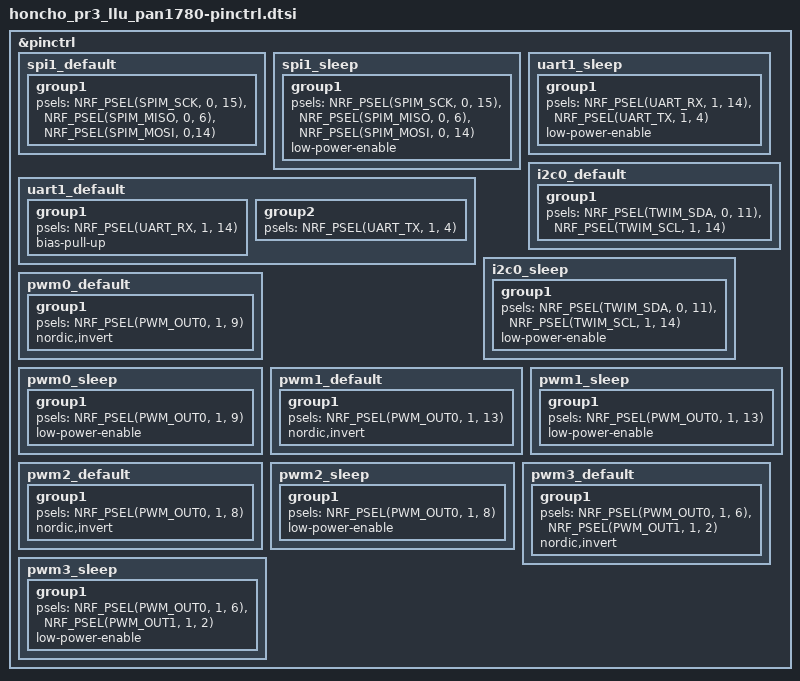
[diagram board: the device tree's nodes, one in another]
/*
 * Copyright (c) 2022 Nordic Semiconductor
 * SPDX-License-Identifier: Apache-2.0
 * Pinouts of file in path EE Team for HTAS -> Documnets 
 * -> General -> Documents -> Firmware -> Nordic Pinout.xlsx
 */
 &pinctrl {
	// uart0_default: uart0_default {
	// 	group1 {
	// 		psels = <NRF_PSEL(UART_TX, 0, 28)>,
	// 				<NRF_PSEL(UART_RX, 0, 29)>;
	// 	};
	// };

	// uart0_sleep: uart0_sleep {
	// 	group1 {
	// 		psels = <NRF_PSEL(UART_TX, 0, 28)>,
	// 			<NRF_PSEL(UART_RX, 0, 29)>;
	// 		low-power-enable;
	// 	};
	// };

	spi1_default: spi1_default {
		group1 {
			psels = <NRF_PSEL(SPIM_SCK, 0, 15)>,
				<NRF_PSEL(SPIM_MISO, 0, 6)>,
				<NRF_PSEL(SPIM_MOSI, 0,14)>;
		};
	};

	spi1_sleep: spi1_sleep {
		group1 {
			psels = <NRF_PSEL(SPIM_SCK, 0, 15)>,
				<NRF_PSEL(SPIM_MISO, 0, 6)>,
				<NRF_PSEL(SPIM_MOSI, 0, 14)>;
			low-power-enable;
		};
	};

	uart1_default: uart1_default {
		group1 {
			psels = <NRF_PSEL(UART_RX, 1, 14)>;		////test point P1.14, th P0.29  AN5
			bias-pull-up;
		};
		group2 {
			psels = <NRF_PSEL(UART_TX, 1, 4)>;		//test point P1.04, SBD C3 P0.28 AN4
		};
	};
	
	uart1_sleep: uart1_sleep {
		group1 {
			psels = <NRF_PSEL(UART_RX, 1, 14)>,
				<NRF_PSEL(UART_TX, 1, 4)>;
			low-power-enable;
		};
	};

	i2c0_default: i2c0_default {
		group1 {
			psels = <NRF_PSEL(TWIM_SDA, 0, 11)>,						//8
				<NRF_PSEL(TWIM_SCL, 1, 14)>;							//6
		};
	};

	i2c0_sleep: i2c0_sleep {
		group1 {
			psels = <NRF_PSEL(TWIM_SDA, 0, 11)>,
				<NRF_PSEL(TWIM_SCL, 1, 14)>;
			low-power-enable;
		};
	};
	
	pwm0_default: pwm0_default {
		group1 {
			psels = <NRF_PSEL(PWM_OUT0, 1, 9)>;
			nordic,invert;
		};
	};

	pwm0_sleep: pwm0_sleep {
		group1 {
			psels = <NRF_PSEL(PWM_OUT0, 1, 9)>;
			low-power-enable;
		};
	};
	pwm1_default: pwm1_default {
		group1 {
			psels = <NRF_PSEL(PWM_OUT0, 1, 13)>;
			nordic,invert;
		};
	};

	pwm1_sleep: pwm1_sleep {
		group1 {
			psels = <NRF_PSEL(PWM_OUT0, 1, 13)>;
			low-power-enable;
		};
	};

	pwm2_default: pwm2_default {
		group1 {
			psels = <NRF_PSEL(PWM_OUT0, 1, 8)>;
			nordic,invert;
		};
	};

	pwm2_sleep: pwm2_sleep {
		group1 {
			psels = <NRF_PSEL(PWM_OUT0, 1, 8)>;
			low-power-enable;
		};
	};

	pwm3_default: pwm3_default {
		group1 {
			psels = <NRF_PSEL(PWM_OUT0, 1, 6)>,
					<NRF_PSEL(PWM_OUT1, 1, 2)>;
			nordic,invert;
		};
	};

	pwm3_sleep: pwm3_sleep {
		group1 {
			psels = <NRF_PSEL(PWM_OUT0, 1, 6)>,
					<NRF_PSEL(PWM_OUT1, 1, 2)>;
			low-power-enable;
		};
	};
	

};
